# CPSW_SL register map
Vendor: Texas Instruments
Peripheral module from a debugger description file (folder am437x).
Registers are 32-bit, access per field, no defined reset value unless marked. A register's access mark holds for its fields unless they carry their own. Offsets are as the file gives them; lines under a group give offsets from that group; [hi:lo] are bit positions; {n}, {i} and the like mark numbered series; 'fields as' and 'values as' point back to an identical list; <NAME> marks a mode.

## CPSW_SL
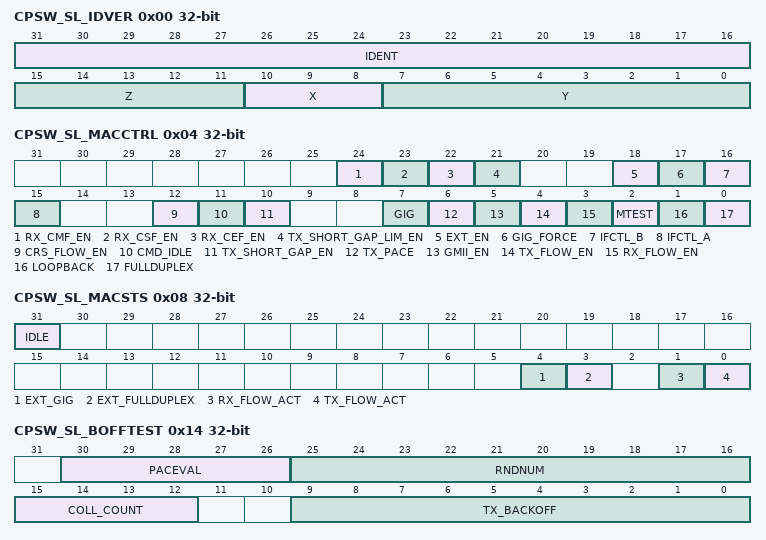
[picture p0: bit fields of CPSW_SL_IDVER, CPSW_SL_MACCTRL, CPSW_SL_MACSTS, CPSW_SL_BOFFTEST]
0x00 CPSW_SL_IDVER ro — CPGMAC_SL ID/VERSION REGISTER
  [31:16] IDENT — Rx Identification Value
  [15:11] Z — Rx Z value (X.Y.Z)
  [10:8] X — Rx X value (major)
  [7:0] Y — Rx Y value (minor)
0x04 CPSW_SL_MACCTRL — CPGMAC_SL MAC CONTROL REGISTER
  [24] RX_CMF_EN rw — RX Copy MAC Control Frames Enable - Enables MAC control frames to be transferred to memory. [[br]]MAC control frames are normally acted upon (if enabled), but not copied to memory. [[br]]MAC control frames that are pause frames will be acted upon if enabled in the MacControl register, regardless of the value of rx_cmf_en. [[br]]Frames transferred to memory due to rx_cmf_en will have the control bit set in their EOP buffer descriptor.
    1=en_2_0x1 (MAC control frames are transferred to memory.); 0=en_1_0x0 (MAC control frames are filtered (but acted upon if enabled).)
  [23] RX_CSF_EN rw — RX Copy Short Frames Enable - Enables frames or fragments shorter than 64 bytes to be copied to memory. [[br]]Frames transferred to memory due to rx_csf_en will have the fragment or undersized bit set in their receive footer. [[br]]Fragments are short frames that contain CRC/align/code errors and undersized are short frames without errors. [[br]]
    1=en_2_0x1 (Short frames are transferred to memory.); 0=en_1_0x0 (Short frames are filtered)
  [22] RX_CEF_EN rw — RX Copy Error Frames Enable - Enables frames containing errors to be transferred to memory. [[br]]The appropriate error bit will be set in the frame receive footer. [[br]]Frames containing errors will be filtered when rx_cef _en is not set.
    1=en_2_0x1 (Frames containing errors are transferred to memory.); 0=en_1_0x0 (Frames containing errors are filtered.)
  [21] TX_SHORT_GAP_LIM_EN rw — Transmit Short Gap Limit Enable When set this bit limits the number of short gap packets transmitted to 100ppm. [[br]]Each time a short gap packet is sent, a counter is loaded with 10,000 and decremented on each wireside clock. [[br]]Another short gap packet will not be sent out until the counter decrements to zero. [[br]]This mode is included to preclude the host from filling up the FIFO and sending every packet out with short gap which would violate the maximum number of packets per second allowed. [[br]]
  [18] EXT_EN rw — Control Enable - Enables the fullduplex and gigabit mode to be selected from the FULLDUPLEX_IN and GIG_IN input signals and not from the fullduplex and gig bits in this register. [[br]]The FULLDUPLEX_MODE bit reflects the actual fullduplex mode selected. [[br]]
  [17] GIG_FORCE rw — Gigabit Mode Force - This bit is used to force the CPGMAC_SL into gigabit mode if the input GMII_MTCLK has been stopped by the PHY. [[br]]
  [16] IFCTL_B rw — Connects to the speed_in input of the respective RMII gasket. [[br]]When using RMII mode:
    1=en_2_0x1 (100Mbps operation); 0=en_1_0x0 (10Mbps operation)
  [15] IFCTL_A rw — Connects to the speed_in input of the respective RMII gasket. [[br]]When using RMII mode:
    values as IFCTL_B
  [12] CRS_FLOW_EN rw — Carrier Sense Flow Control Enable[[br]] When set this bit enables the GMII_MCRS (carrier sense) to be used as a hardware flow control in fullduplex mode.
  [11] CMD_IDLE rw — Command Idle
    1=en_2_0x1 (Idle Commanded (read idle in MacStatus)); 0=en_1_0x0 (Idle not commanded)
  [10] TX_SHORT_GAP_EN rw — Transmit Short Gap Enable
    1=en_2_0x1 (Transmit with a short IPG (when TX_SHORT_GAP input is asserted) is enabled.); 0=en_1_0x0 (Transmit with a short IPG is disabled)
  [7] GIG rw — Gigabit Mode
    1=en_2_0x1 (Gigabit mode (full duplex only) The GIG_OUT output is the value of this bit.); 0=en_1_0x0 (10/100 mode)
  [6] TX_PACE rw — Transmit Pacing Enable
    1=en_2_0x1 (Transmit Pacing Enabled); 0=en_1_0x0 (Transmit Pacing Disabled)
  [5] GMII_EN rw — GMII Enable
    1=en_2_0x1 (GMII RX and TX released from reset.); 0=en_1_0x0 (GMII RX and TX held in reset.)
  [4] TX_FLOW_EN rw — Transmit Flow Control Enable - Determines if incoming pause frames are acted upon in full-duplex mode. [[br]]Incoming pause frames are not acted upon in half-duplex mode regardless of this bit setting. [[br]]The RX_MBP_Enable bits determine whether or not received pause frames are transferred to memory. [[br]]
    1=en_2_0x1 (Transmit Flow Control Enabled. Full-duplex mode - Incoming pause frames are acted upon.); 0=en_1_0x0 (Transmit Flow Control Disabled. Full-duplex mode - Incoming pause frames are not acted upon.)
  [3] RX_FLOW_EN rw — Receive Flow Control Enable
    1=en_2_0x1 (Receive Flow Control Enabled Half-duplex mode - Collisions are initiated when receive flow control is triggered. Full-duplex mode - Outgoing pause frames are sent when receive flow control is triggered.); 0=en_1_0x0 (Receive Flow Control Disabled Half-duplex mode - No flow control generated collisions are sent. Full-duplex mode - No outgoing pause frames are sent.)
  [2] MTEST rw — Manufacturing Test mode - This bit must be set to allow writes to the Backoff_Test and PauseTimer registers.
  [1] LOOPBACK rw — Loop Back Mode - Loopback mode forces internal fullduplex mode regardless of whether the fullduplex bit is set or not. [[br]]The loopback bit should be changed only when GMII_en is deasserted.
    1=en_2_0x1 (Loop Back Mode enabled); 0=en_1_0x0 (Not looped back)
  [0] FULLDUPLEX rw — Full Duplex mode - Gigabit mode forces fullduplex mode regardless of whether the fullduplex bit is set or not. [[br]]The FULLDUPLEX_OUT output is the value of this register bit
    1=en_2_0x1 (Full duplex mode); 0=en_1_0x0 (Half duplex mode)
0x08 CPSW_SL_MACSTS ro — CPGMAC_SL MAC STATUS REGISTER
  [31] IDLE — CPGMAC_SL IDLE - The CPGMAC_SL is in the idle state (valid after an idle command)
    1=en_2_0x1 (The CPGMAC_SL is in the idle state.); 0=en_1_0x0 (The CPGMAC_SL is not in the idle state.)
  [4] EXT_GIG — External GIG - This is the value of the EXT_GIG input bit.
  [3] EXT_FULLDUPLEX — External Fullduplex - This is the value of the EXT_FULLDUPLEX input bit.
  [1] RX_FLOW_ACT — Receive Flow Control Active - When asserted, indicates that receive flow control is enabled and triggered.
  [0] TX_FLOW_ACT — Transmit Flow Control Active - When asserted, this bit indicates that the pause time period is being observed for a received pause frame. [[br]]No new transmissions will begin while this bit is asserted except for the transmission of pause frames. [[br]]Any transmission in progress when this bit is asserted will complete. [[br]]
0x0C CPSW_SL_SOFT_RESET — CPGMAC_SL SOFT RESET REGISTER
  [0] SOFT_RESET rw — Software reset - Writing a one to this bit causes the CPGMAC_SL logic to be reset. [[br]]After writing a one to this bit, it may be polled to determine if the reset has occurred. [[br]]If a one is read, the reset has not yet occurred. [[br]]If a zero is read then reset has occurred. [[br]]
0x10 CPSW_SL_RX_MAXLEN — CPGMAC_SL RX MAXIMUM LENGTH REGISTER
  [13:0] RX_MAXLEN rw — RX Maximum Frame Length - This field determines the maximum length of a received frame. [[br]]The reset value is 1518 (dec). [[br]]Frames with byte counts greater than rx_maxlen are long frames. [[br]]Long frames with no errors are oversized frames. [[br]]Long frames with CRC, code, or alignment error are jabber frames. [[br]]The maximum value is 16,383. [[br]]
0x14 CPSW_SL_BOFFTEST — CPGMAC_SL BACKOFF TEST REGISTER
  [30:26] PACEVAL rw — Pacing Register Current Value. [[br]]A non-zero value in this field indicates that transmit pacing is active. [[br]]A transmit frame collision or deferral causes paceval to loaded with decimal 31, good frame transmissions (with no collisions or deferrals) cause paceval to be decremented down to zero. [[br]]When paceval is nonzero, the transmitter delays 4 IPGs between new frame transmissions after each successfully transmitted frame that had no deferrals or collisions. [[br]]Transmit pacing helps reduce "capture" effects improving overall network bandwidth. [[br]]
  [25:16] RNDNUM rw — Backoff Random Number Generator - This field allows the Backoff Random Number Generator to be read (or written in test mode only). [[br]]This field can be written only when mtest has previously been set. [[br]]Reading this field returns the generator's current value. [[br]]The value is reset to zero and begins counting on the clock after the deassertion of reset. [[br]]
  [15:12] COLL_COUNT ro — Collision Count - The number of collisions the current frame has experienced.
  [9:0] TX_BACKOFF ro — Backoff Count - This field allows the current value of the backoff counter to be observed for test purposes. [[br]]This field is loaded automatically according to the backoff algorithm, and is decremented by one for each slot time after the collision. [[br]]
0x18 CPSW_SL_RX_PAUSE ro — CPGMAC_SL RECEIVE PAUSE TIMER REGISTER
  [15:0] RX_PAUSETIMER — RX Pause Timer Value - This field allows the contents of the receive pause timer to be observed (and written in test mode). [[br]]The receive pause timer is loaded with 0xFF00 when the CPGMAC_SL sends an outgoing pause frame (with pause time of 0xFFFF). [[br]]The receive pause timer is decremented at slot time intervals. [[br]]If the receive pause timer decrements to zero, then another outgoing pause frame will be sent and the load/decrement process will be repeated.
0x1C CPSW_SL_TX_PAUSE ro — CPGMAC_SL TRANSMIT PAUSE TIMER REGISTER
  [15:0] TX_PAUSETIMER — TX Pause Timer Value - This field allows the contents of the transmit pause timer to be observed (and written in test mode). [[br]]The transmit pause timer is loaded by a received (incoming) pause frame, and then decremented, at slottime intervals, down to zero at which time CPGMAC_SL transmit frames are again enabled.
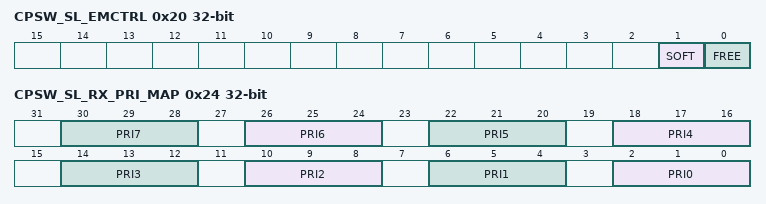
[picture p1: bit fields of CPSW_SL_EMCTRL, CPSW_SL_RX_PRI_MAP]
0x20 CPSW_SL_EMCTRL — CPGMAC_SL EMULATION CONTROL REGISTER
  [1] SOFT rw — Emulation Soft Bit
  [0] FREE rw — Emulation Free Bit
0x24 CPSW_SL_RX_PRI_MAP — CPGMAC_SL RX PKT PRIORITY TO HEADER PRIORITY MAPPING REGISTER
  [4n+2:4n] PRI{n} rw (n=0..7) — Priority [[br]]{n} - A packet priority of {0x0+n} is mapped (changed) to this value.
0x28 CPSW_SL_TX_GAP — TRANSMIT INTER-PACKET GAP REGISTER
  [8:0] TX_GAP rw — Transmit Inter-Packet Gap
